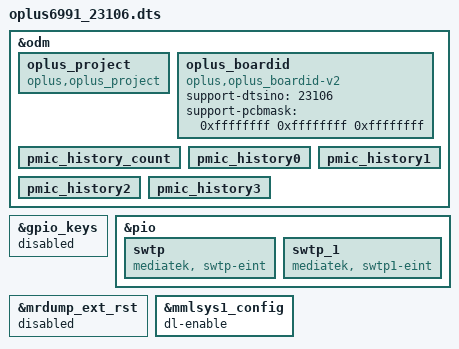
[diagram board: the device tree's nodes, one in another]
// SPDX-License-Identifier: (GPL-2.0 OR MIT)
/*
 * Copyright (C) 2022 MediaTek Inc.
 */
#include "k6991v1_64.dts"
#include <dt-bindings/pinctrl/mt6373-pinfunc.h>

&odm {
	/*OPLUS_FEATURE_OEM_OCDT oplus project start */
	oplus_project:oplus_project {
		compatible = "oplus,oplus_project";
	};

	oplus_boardid:oplus_boardid {
        compatible = "oplus,oplus_boardid-v2";
        support-dtsino=<23106>;//only one u32
        /*first one is low 32bit, last one is highest 32bit, must be 32-bit for 4gpios*/
        support-pcbmask=<0xffffffff 0xffffffff 0xffffffff>;
    };

    pmic_history_count:pmic_history_count {
    };
    pmic_history0:pmic_history0 {
    };
    pmic_history1:pmic_history1 {
    };
    pmic_history2:pmic_history2 {
    };
    pmic_history3:pmic_history3 {
    };

};


&gpio_keys {
    status = "disabled";
};

&pio {
	//#ifdef OPLUS_VENDOR_SWTP
	swtp: swtp {
		compatible = "mediatek, swtp-eint";
	};
	 swtp_1: swtp_1 {
        compatible = "mediatek, swtp1-eint";
    };
	//#endif  /*OPLUS_VENDOR_SWTP*/
};

&mrdump_ext_rst	{
	status = "disabled";
};

&mmlsys1_config {
	dl-enable;
};

/*End of this file, DO NOT ADD ANYTHING HERE*/

